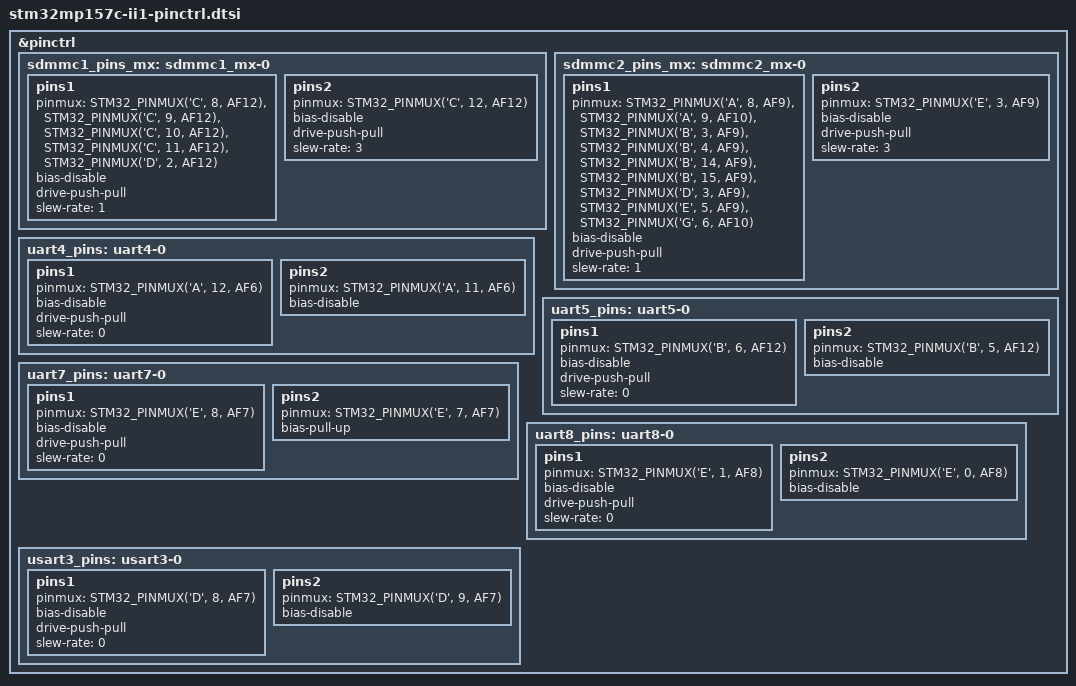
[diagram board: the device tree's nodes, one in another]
// SPDX-License-Identifier: (GPL-2.0+ OR BSD-3-Clause)
/*
 * Copyright (C) 2023  Braiins Systems s.r.o.
 *
 * This file is part of Braiins Open-Source Initiative (BOSI).
 *
 * BOSI is free software: you can redistribute it and/or modify
 * it under the terms of the GNU General Public License as published by
 * the Free Software Foundation, either version 3 of the License, or
 * (at your option) any later version.
 *
 * This program is distributed in the hope that it will be useful,
 * but WITHOUT ANY WARRANTY; without even the implied warranty of
 * MERCHANTABILITY or FITNESS FOR A PARTICULAR PURPOSE.  See the
 * GNU General Public License for more details.
 *
 * You should have received a copy of the GNU General Public License
 * along with this program.  If not, see <https://www.gnu.org/licenses/>.
 *
 * Please, keep in mind that we may also license BOSI or any part thereof
 * under a proprietary license. For more information on the terms and conditions
 * of such proprietary license or if you have any other questions, please
 * contact us at opensource@braiins.com.
 */

#include <dt-bindings/pinctrl/stm32-pinfunc.h>

&pinctrl {
	sdmmc1_pins_mx: sdmmc1_mx-0 {
		pins1 {
			pinmux = <STM32_PINMUX('C', 8, AF12)>, /* SDMMC1_D0 */
				 <STM32_PINMUX('C', 9, AF12)>, /* SDMMC1_D1 */
				 <STM32_PINMUX('C', 10, AF12)>, /* SDMMC1_D2 */
				 <STM32_PINMUX('C', 11, AF12)>, /* SDMMC1_D3 */
				 <STM32_PINMUX('D', 2, AF12)>; /* SDMMC1_CMD */
			bias-disable;
			drive-push-pull;
			slew-rate = <1>;
		};
		pins2 {
			pinmux = <STM32_PINMUX('C', 12, AF12)>; /* SDMMC1_CK */
			bias-disable;
			drive-push-pull;
			slew-rate = <3>;
		};
	};

	sdmmc2_pins_mx: sdmmc2_mx-0 {
		pins1 {
			pinmux = <STM32_PINMUX('A', 8, AF9)>, /* SDMMC2_D4 */
				 <STM32_PINMUX('A', 9, AF10)>, /* SDMMC2_D5 */
				 <STM32_PINMUX('B', 3, AF9)>, /* SDMMC2_D2 */
				 <STM32_PINMUX('B', 4, AF9)>, /* SDMMC2_D3 */
				 <STM32_PINMUX('B', 14, AF9)>, /* SDMMC2_D0 */
				 <STM32_PINMUX('B', 15, AF9)>, /* SDMMC2_D1 */
				 <STM32_PINMUX('D', 3, AF9)>, /* SDMMC2_D7 */
				 <STM32_PINMUX('E', 5, AF9)>, /* SDMMC2_D6 */
				 <STM32_PINMUX('G', 6, AF10)>; /* SDMMC2_CMD */
			bias-disable;
			drive-push-pull;
			slew-rate = <1>;
		};
		pins2 {
			pinmux = <STM32_PINMUX('E', 3, AF9)>; /* SDMMC2_CK */
			bias-disable;
			drive-push-pull;
			slew-rate = <3>;
		};
	};

	uart4_pins: uart4-0 {
		pins1 {
			pinmux = <STM32_PINMUX('A', 12, AF6)>; /* UART4_TX */
			bias-disable;
			drive-push-pull;
			slew-rate = <0>;
		};
		pins2 {
			pinmux = <STM32_PINMUX('A', 11, AF6)>; /* UART4_RX */
			bias-disable;
		};
	};

	uart5_pins: uart5-0 {
		pins1 {
			pinmux = <STM32_PINMUX('B', 6, AF12)>; /* UART5_TX */
			bias-disable;
			drive-push-pull;
			slew-rate = <0>;
		};
		pins2 {
			pinmux = <STM32_PINMUX('B', 5, AF12)>; /* UART5_RX */
			bias-disable;
		};
	};

	uart7_pins: uart7-0 {
		pins1 {
			pinmux = <STM32_PINMUX('E', 8, AF7)>; /* UART7_TX */
			bias-disable;
			drive-push-pull;
			slew-rate = <0>;
		};
		pins2 {
			pinmux = <STM32_PINMUX('E', 7, AF7)>; /* UART7_RX */
			bias-pull-up;
		};
	};

	uart8_pins: uart8-0 {
		pins1 {
			pinmux = <STM32_PINMUX('E', 1, AF8)>; /* UART8_TX */
			bias-disable;
			drive-push-pull;
			slew-rate = <0>;
		};
		pins2 {
			pinmux = <STM32_PINMUX('E', 0, AF8)>; /* UART8_RX */
			bias-disable;
		};
	};

	usart3_pins: usart3-0 {
		pins1 {
			pinmux = <STM32_PINMUX('D', 8, AF7)>; /* USART3_TX */
			bias-disable;
			drive-push-pull;
			slew-rate = <0>;
		};
		pins2 {
			pinmux = <STM32_PINMUX('D', 9, AF7)>; /* USART3_RX */
			bias-disable;
		};
	};
};
